VERSION ""

NS_ :

BS_:

BU_: DSC

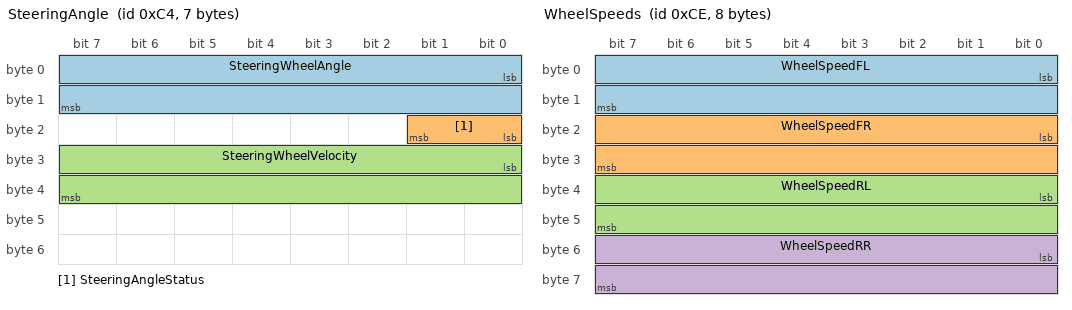
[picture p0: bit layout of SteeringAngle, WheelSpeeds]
BO_ 196 SteeringAngle: 7 DSC
 SG_ SteeringWheelAngle : 0|16@1- (0.043737,0) [-1433|1433] "deg" Vector__XXX
 SG_ SteeringAngleStatus : 16|2@1+ (1,0) [0|3] "" Vector__XXX
 SG_ SteeringWheelVelocity : 24|16@1- (0.043737,0) [-1433|1433] "deg/s" Vector__XXX

BO_ 206 WheelSpeeds: 8 DSC
 SG_ WheelSpeedFL : 0|16@1- (0.0625,0) [-300|300] "km/h" Vector__XXX
 SG_ WheelSpeedFR : 16|16@1- (0.0625,0) [-300|300] "km/h" Vector__XXX
 SG_ WheelSpeedRL : 32|16@1- (0.0625,0) [-300|300] "km/h" Vector__XXX
 SG_ WheelSpeedRR : 48|16@1- (0.0625,0) [-300|300] "km/h" Vector__XXX

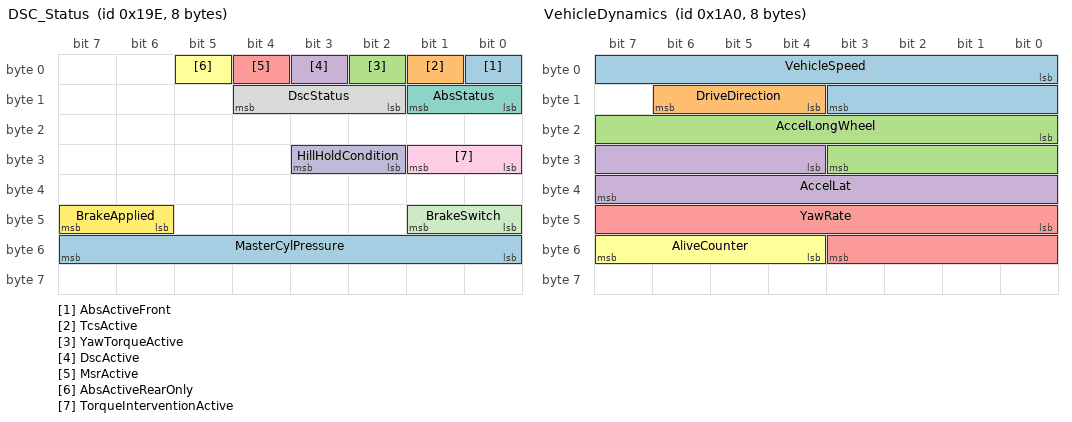
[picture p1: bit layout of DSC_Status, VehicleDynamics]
BO_ 414 DSC_Status: 8 DSC
 SG_ AbsActiveFront : 0|1@1+ (1,0) [0|1] "" Vector__XXX
 SG_ TcsActive : 1|1@1+ (1,0) [0|1] "" Vector__XXX
 SG_ YawTorqueActive : 2|1@1+ (1,0) [0|1] "" Vector__XXX
 SG_ DscActive : 3|1@1+ (1,0) [0|1] "" Vector__XXX
 SG_ MsrActive : 4|1@1+ (1,0) [0|1] "" Vector__XXX
 SG_ AbsActiveRearOnly : 5|1@1+ (1,0) [0|1] "" Vector__XXX
 SG_ AbsStatus : 8|2@1+ (1,0) [0|3] "" Vector__XXX
 SG_ DscStatus : 10|3@1+ (1,0) [0|7] "" Vector__XXX
 SG_ TorqueInterventionActive : 24|2@1+ (1,0) [0|3] "" Vector__XXX
 SG_ HillHoldCondition : 26|2@1+ (1,0) [0|3] "" Vector__XXX
 SG_ BrakeSwitch : 40|2@1+ (1,0) [0|3] "" Vector__XXX
 SG_ BrakeApplied : 46|2@1+ (1,0) [0|3] "" Vector__XXX
 SG_ MasterCylPressure : 48|8@1+ (1,0) [0|254] "bar" Vector__XXX

BO_ 416 VehicleDynamics: 8 DSC
 SG_ VehicleSpeed : 0|12@1+ (0.1,0) [0|300] "km/h" Vector__XXX
 SG_ DriveDirection : 12|3@1+ (1,0) [0|7] "" Vector__XXX
 SG_ AccelLongWheel : 16|12@1- (0.0245166,0) [-9.81|9.81] "m/s2" Vector__XXX
 SG_ AccelLat : 28|12@1- (0.02501,0) [-51.2|51.2] "m/s2" Vector__XXX
 SG_ YawRate : 40|12@1- (0.05,0) [-90|90] "deg/s" Vector__XXX
 SG_ AliveCounter : 52|4@1+ (1,0) [0|14] "" Vector__XXX

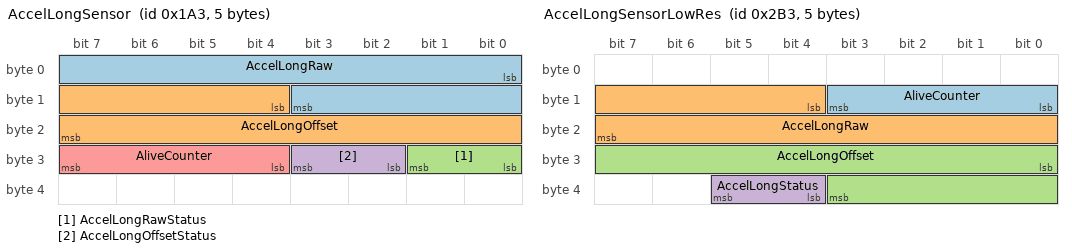
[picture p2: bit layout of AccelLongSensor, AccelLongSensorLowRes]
BO_ 419 AccelLongSensor: 5 DSC
 SG_ AccelLongRaw : 0|12@1- (0.01,0) [-20.47|20.47] "m/s2" Vector__XXX
 SG_ AccelLongOffset : 12|12@1- (0.01,0) [-2.34|2.34] "m/s2" Vector__XXX
 SG_ AccelLongRawStatus : 24|2@1+ (1,0) [0|3] "" Vector__XXX
 SG_ AccelLongOffsetStatus : 26|2@1+ (1,0) [0|3] "" Vector__XXX
 SG_ AliveCounter : 28|4@1+ (1,0) [0|14] "" Vector__XXX

BO_ 691 AccelLongSensorLowRes: 5 DSC
 SG_ AliveCounter : 8|4@1+ (1,0) [0|14] "" Vector__XXX
 SG_ AccelLongRaw : 12|12@1+ (0.025,-51.2) [-51.2|51.175] "m/s2" Vector__XXX
 SG_ AccelLongOffset : 24|12@1+ (0.025,-51.2) [-2.34|2.34] "m/s2" Vector__XXX
 SG_ AccelLongStatus : 36|2@1+ (1,0) [0|3] "" Vector__XXX

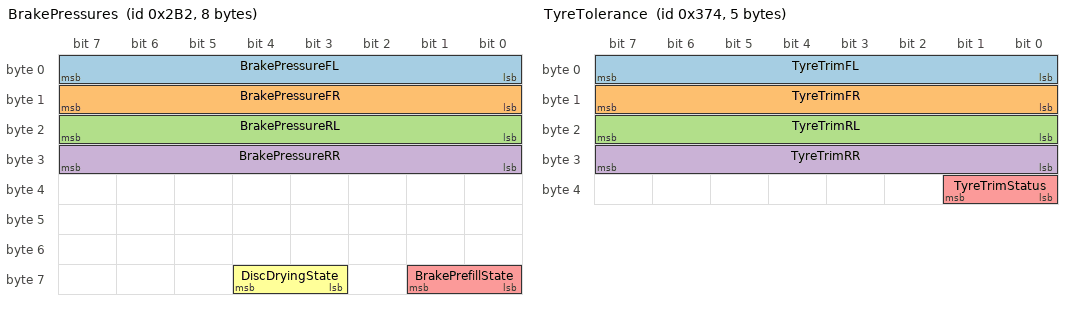
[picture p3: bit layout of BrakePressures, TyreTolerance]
BO_ 690 BrakePressures: 8 DSC
 SG_ BrakePressureFL : 0|8@1+ (1,0) [0|254] "bar" Vector__XXX
 SG_ BrakePressureFR : 8|8@1+ (1,0) [0|254] "bar" Vector__XXX
 SG_ BrakePressureRL : 16|8@1+ (1,0) [0|254] "bar" Vector__XXX
 SG_ BrakePressureRR : 24|8@1+ (1,0) [0|254] "bar" Vector__XXX
 SG_ BrakePrefillState : 56|2@1+ (1,0) [0|3] "" Vector__XXX
 SG_ DiscDryingState : 59|2@1+ (1,0) [0|3] "" Vector__XXX

BO_ 884 TyreTolerance: 5 DSC
 SG_ TyreTrimFL : 0|8@1- (0.1,0) [-12.7|0] "%" Vector__XXX
 SG_ TyreTrimFR : 8|8@1- (0.1,0) [-12.7|0] "%" Vector__XXX
 SG_ TyreTrimRL : 16|8@1- (0.1,0) [-12.7|0] "%" Vector__XXX
 SG_ TyreTrimRR : 24|8@1- (0.1,0) [-12.7|0] "%" Vector__XXX
 SG_ TyreTrimStatus : 32|2@1+ (1,0) [0|3] "" Vector__XXX

CM_ "Mk60e5 DSC PT-CAN broadcast, trimmed for track logging. Covers unmodified M3 (software 7846816A) and non-M (software 6862873A) DSC; frame layouts are the same on both except where noted. Checksums are left out; alive counters are included where they are useful.";
CM_ BO_ 196 "Steering angle relayed from the F-CAN steering sensor (0x0C9), 10 ms. Only meaningful with a steering sensor fitted. Bytes 5-6 are constant.";
CM_ SG_ 196 SteeringWheelAngle "Steering-wheel angle. Sign convention unverified.";
CM_ SG_ 196 SteeringWheelVelocity "Steering-wheel angular velocity, relayed from a sub-channel of the sensor frame and held between updates. Same raw scaling as the angle.";
CM_ SG_ 196 SteeringAngleStatus "Sensor status. 0 and 1 are passed through from the sensor; the meaning of 1 is a best guess.";
CM_ BO_ 206 "Wheel speeds, 20 ms. Raw per-wheel speed: no tyre-tolerance trim, not vref. Reads 0 below about 0.6 km/h. Negative when the wheel's direction is latched as reverse (direction updates below 55 km/h only).";
CM_ BO_ 414 "DSC/ABS status, 20 ms. On non-M, byte 0 bit 6 can also be set (meaning unknown; never set on M3).";
CM_ SG_ 414 AbsActiveFront "A front wheel is in an ABS cycle.";
CM_ SG_ 414 TcsActive "Traction control (brake or engine) intervening.";
CM_ SG_ 414 YawTorqueActive "Yaw control is requesting an engine torque cut.";
CM_ SG_ 414 DscActive "DSC (yaw control) function active.";
CM_ SG_ 414 MsrActive "MSR (engine drag torque control) active.";
CM_ SG_ 414 AbsActiveRearOnly "A rear wheel is under ABS control and no front is (EBD-style rear control).";
CM_ SG_ 414 AbsStatus "2 = ABS switched off by a fault reaction, or ABS lamp on with ABS degraded.";
CM_ SG_ 414 DscStatus "First match wins, in order 2, 6, 3, 1, 4, else 0.";
CM_ SG_ 414 TorqueInterventionActive "1 = yaw-control torque request, or TCS active with a large torque cut (latched).";
CM_ SG_ 414 HillHoldCondition "1 = hill-start assist condition: driver pressure above threshold, car on a slope it can hold. Exact meaning (armed vs holding) unconfirmed.";
CM_ SG_ 414 BrakeSwitch "Brake-light switch. Reads 3 (invalid) unless 0x130 (terminal status) is received with byte 0 bits 0-1 = 1.";
CM_ SG_ 414 BrakeApplied "1 = brake switch on or any valid wheel pressure > 6 bar.";
CM_ SG_ 414 MasterCylPressure "Master-cylinder (driver) pressure, integer bar, clamped 0..254.";
CM_ BO_ 416 "Vehicle speed and body motion, 20 ms.";
CM_ SG_ 416 VehicleSpeed "Mean of the two FRONT wheel speeds (not vref, no tyre trim). Clamped to 300 km/h.";
CM_ SG_ 416 DriveDirection "From the front-wheel direction bits and the standstill detector.";
CM_ SG_ 416 AccelLongWheel "Longitudinal accel derived from the FRONT wheel accelerations, not the accelerometer. 0.0025 g/bit, clamped +/-1 g, low-passed (1st-order IIR, alpha 1/32), so it lags. Free of road slope, but wrong under front wheel slip/lock.";
CM_ SG_ 416 AccelLat "Lateral accel from the sensor cluster, offset-corrected. Sign unverified.";
CM_ SG_ 416 YawRate "Yaw rate from the sensor cluster, offset-corrected, clipped to +/-90 deg/s. Sign unverified.";
CM_ SG_ 416 AliveCounter "Steps every frame, 0..14 (15 skipped).";
CM_ BO_ 419 "Longitudinal accelerometer, 20 ms. M3 only: non-M software never transmits this frame (use 0x2B3 there). Preferred over 0x2B3 on M3: same values at finer resolution and a faster rate. No offset-corrected sensor ax is broadcast: corrected = AccelLongRaw - AccelLongOffset (make it a math channel).";
CM_ SG_ 419 AccelLongRaw "Raw accelerometer ax: unfiltered, no zero-offset correction, includes road gradient.";
CM_ SG_ 419 AccelLongOffset "Learned accelerometer zero offset (+/-0.238 g max), same scale as AccelLongRaw.";
CM_ SG_ 419 AccelLongRawStatus "Value 1 is never sent for the raw signal.";
CM_ SG_ 419 AccelLongOffsetStatus "1 = offset probably not learned yet.";
CM_ SG_ 419 AliveCounter "Steps every frame, 0..14 (15 skipped).";
CM_ BO_ 691 "Longitudinal accelerometer, low resolution, 50 ms. Same raw value and learned offset as 0x1A3, at 0.025 m/s2/bit. Sent by both M3 and non-M, but only while the DSC reports the accelerometer signal as available, so expect it to be missing with no sensor cluster connected. On non-M this is the only accelerometer ax frame; on M3 prefer 0x1A3. Corrected = AccelLongRaw - AccelLongOffset. Byte 0 is a checksum (not decoded).";
CM_ SG_ 691 AccelLongRaw "Raw accelerometer ax: unfiltered, no zero-offset correction, includes road gradient. Offset-binary on the wire (raw 2048 = 0).";
CM_ SG_ 691 AccelLongOffset "Learned accelerometer zero offset (+/-0.238 g max), same scale as AccelLongRaw.";
CM_ SG_ 691 AccelLongStatus "Status of the accelerometer signal. Value 1 is never sent.";
CM_ SG_ 691 AliveCounter "Steps every frame, 0..14 (15 skipped).";
CM_ BO_ 690 "Wheel brake pressures and brake pre-fill state, 20 ms.";
CM_ SG_ 690 BrakePressureFL "Measured/modelled wheel pressure, integer bar, clamped 0..254.";
CM_ SG_ 690 BrakePrefillState "Brake pre-fill on fast throttle lift. 0 = not coded or inhibited, 1 = armed, 2 = active.";
CM_ SG_ 690 DiscDryingState "Wet-disc drying (wiper-triggered). 0 = not coded or inhibited, 1 = armed, 2 = active.";
CM_ BO_ 884 "Learned per-wheel tyre tolerance trims, 1 s. Factor applied to the wheel's speed = 1 + TyreTrim/100. Trims are normalised so the slowest-turning wheel is 0; a negative trim means that wheel turns faster by that much. Clamped at -12.7 %.";
CM_ SG_ 884 TyreTrimStatus "0 after power-up; changes to 1 once the learner has adapted (typically after 1-2 km of driving).";
BA_DEF_ BO_  "GenMsgCycleTime" INT 0 65535;
BA_DEF_DEF_  "GenMsgCycleTime" 0;
BA_ "GenMsgCycleTime" BO_ 196 10;
BA_ "GenMsgCycleTime" BO_ 206 20;
BA_ "GenMsgCycleTime" BO_ 414 20;
BA_ "GenMsgCycleTime" BO_ 416 20;
BA_ "GenMsgCycleTime" BO_ 419 20;
BA_ "GenMsgCycleTime" BO_ 690 20;
BA_ "GenMsgCycleTime" BO_ 691 50;
BA_ "GenMsgCycleTime" BO_ 884 1000;
VAL_ 196 SteeringWheelAngle -32768 "Invalid" ;
VAL_ 196 SteeringWheelVelocity -32768 "Invalid" ;
VAL_ 196 SteeringAngleStatus 0 "Valid" 1 "NotCalibrated" 2 "SensorStatusInvalid" 3 "NoData" ;
VAL_ 206 WheelSpeedFL -32768 "Invalid" ;
VAL_ 206 WheelSpeedFR -32768 "Invalid" ;
VAL_ 206 WheelSpeedRL -32768 "Invalid" ;
VAL_ 206 WheelSpeedRR -32768 "Invalid" ;
VAL_ 414 AbsStatus 0 "Normal" 2 "OffOrDegraded" ;
VAL_ 414 DscStatus 0 "Normal" 1 "DscOff" 2 "Failed" 3 "SteeringAngleInvalid" 4 "ModeLamp_DTC_MDM" 6 "Initialising_SensorFault" ;
VAL_ 414 TorqueInterventionActive 0 "Inactive" 1 "Active" ;
VAL_ 414 HillHoldCondition 0 "Inactive" 1 "Active" 3 "NotAvailable" ;
VAL_ 414 BrakeSwitch 0 "Off" 1 "On" 2 "Fault" 3 "Invalid" ;
VAL_ 414 BrakeApplied 0 "NotBraking" 1 "Braking" 2 "SwitchInvalid" 3 "NoWheelPressureValid" ;
VAL_ 414 MasterCylPressure 255 "Invalid" ;
VAL_ 416 VehicleSpeed 4095 "Invalid" ;
VAL_ 416 DriveDirection 0 "Standstill" 1 "Forward" 2 "Reverse" 3 "MovingDirectionUnknown" 7 "Invalid" ;
VAL_ 416 AccelLongWheel -2048 "Invalid" ;
VAL_ 416 AccelLat -2048 "Invalid" ;
VAL_ 416 YawRate -2048 "Invalid" ;
VAL_ 419 AccelLongRaw -2048 "Invalid" ;
VAL_ 419 AccelLongOffset -2048 "Invalid" ;
VAL_ 419 AccelLongRawStatus 0 "Valid" 2 "Invalid" ;
VAL_ 419 AccelLongOffsetStatus 0 "Valid" 1 "NotLearned" 2 "Invalid" ;
VAL_ 691 AccelLongRaw 4095 "Invalid" ;
VAL_ 691 AccelLongOffset 4095 "Invalid" ;
VAL_ 691 AccelLongStatus 0 "Valid" 2 "Invalid" ;
VAL_ 690 BrakePressureFL 255 "Invalid" ;
VAL_ 690 BrakePressureFR 255 "Invalid" ;
VAL_ 690 BrakePressureRL 255 "Invalid" ;
VAL_ 690 BrakePressureRR 255 "Invalid" ;
VAL_ 690 BrakePrefillState 0 "OffOrInhibited" 1 "Armed" 2 "Active" ;
VAL_ 690 DiscDryingState 0 "OffOrInhibited" 1 "Armed" 2 "Active" ;
VAL_ 884 TyreTrimStatus 0 "NotLearned" 1 "Learned" ;
